VERSION ""

NS_ :

BS_:

BU_: Chassis Steering ADAS Localization

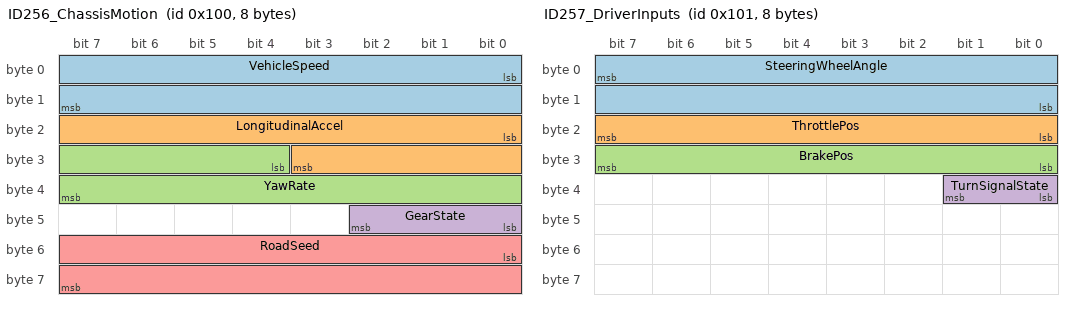
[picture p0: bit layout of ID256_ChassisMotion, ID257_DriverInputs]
BO_ 256 ID256_ChassisMotion: 8 Chassis
 SG_ VehicleSpeed : 0|16@1+ (0.01,0) [0|100] "m/s" Vector__XXX
 SG_ LongitudinalAccel : 16|12@1- (0.01,0) [-20.48|20.47] "m/s^2" Vector__XXX
 SG_ YawRate : 28|12@1- (0.002,0) [-4.096|4.095] "rad/s" Vector__XXX
 SG_ GearState : 40|3@1+ (1,0) [0|7] "" Vector__XXX
 SG_ RoadSeed : 48|16@1+ (1,0) [0|65535] "" Vector__XXX

BO_ 257 ID257_DriverInputs: 8 Steering
 SG_ SteeringWheelAngle : 7|16@0- (0.1,0) [-720|720] "deg" Vector__XXX
 SG_ ThrottlePos : 16|8@1+ (0.005,0) [0|1] "ratio" Vector__XXX
 SG_ BrakePos : 24|8@1+ (0.005,0) [0|1] "ratio" Vector__XXX
 SG_ TurnSignalState : 32|2@1+ (1,0) [0|3] "" Vector__XXX

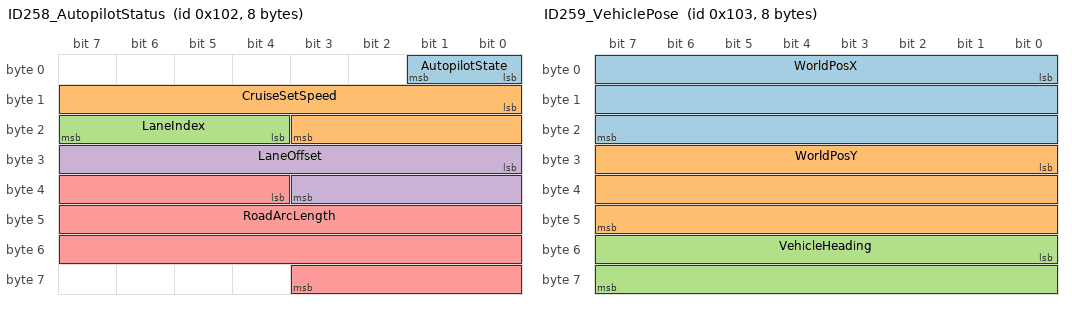
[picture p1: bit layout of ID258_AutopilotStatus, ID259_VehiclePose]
BO_ 258 ID258_AutopilotStatus: 8 ADAS
 SG_ AutopilotState : 0|2@1+ (1,0) [0|3] "" Vector__XXX
 SG_ CruiseSetSpeed : 8|12@1+ (0.02,0) [0|81.9] "m/s" Vector__XXX
 SG_ LaneIndex : 20|4@1+ (1,0) [0|15] "" Vector__XXX
 SG_ LaneOffset : 24|12@1- (0.005,0) [-10.24|10.235] "m" Vector__XXX
 SG_ RoadArcLength : 36|24@1+ (0.05,0) [0|838860] "m" Vector__XXX

BO_ 259 ID259_VehiclePose: 8 Localization
 SG_ WorldPosX : 0|24@1- (0.02,0) [-167772|167772] "m" Vector__XXX
 SG_ WorldPosY : 24|24@1- (0.02,0) [-167772|167772] "m" Vector__XXX
 SG_ VehicleHeading : 48|16@1- (0.0001,0) [-3.2768|3.2767] "rad" Vector__XXX

VAL_ 256 GearState 0 "Park" 1 "Reverse" 2 "Neutral" 3 "Drive" ;
VAL_ 257 TurnSignalState 0 "Off" 1 "Left" 2 "Right" ;
VAL_ 258 AutopilotState 0 "Unavailable" 1 "Standby" 2 "Active" ;
